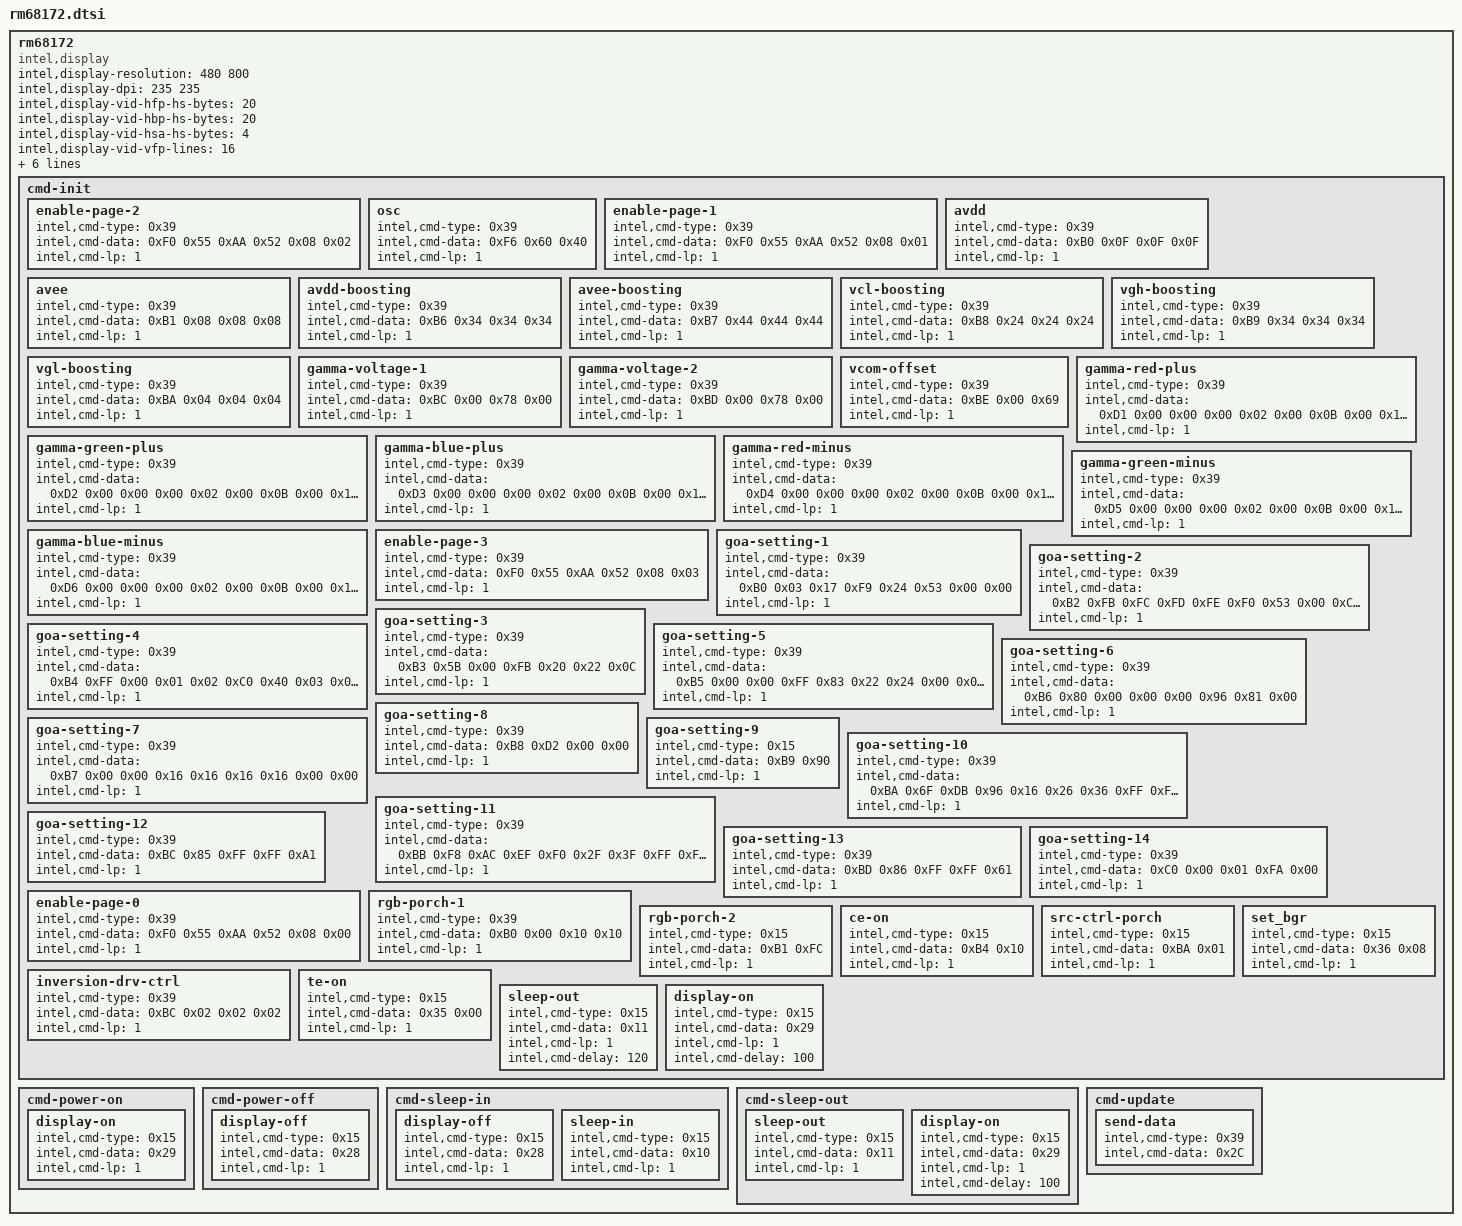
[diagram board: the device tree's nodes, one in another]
	rm68172 {
		compatible = "intel,display";
		intel,display-resolution= <480 800>;
		intel,display-dpi= <235 235>;

		/* MIPI-DSI video mode settings */
		intel,display-vid-hfp-hs-bytes = <20>;
		intel,display-vid-hbp-hs-bytes = <20>;
		intel,display-vid-hsa-hs-bytes = <4>;
		intel,display-vid-vfp-lines = <16>;
		intel,display-vid-vbp-lines = <16>;
		intel,display-vid-vsa-lines = <2>;

		intel,display-vid-mode = "burst";
		intel,display-vid-id = <0>;
		intel,display-vid-pixel = "24packed";

		intel,display-reset = <1 1 0 5 1 50>;

		cmd-init {
			enable-page-2 {
				intel,cmd-type = <0x39>;
				intel,cmd-data = <0xF0 0x55 0xAA 0x52 0x08 0x02>;
				intel,cmd-lp = <1>;
			};
			osc {
				intel,cmd-type = <0x39>;
				intel,cmd-data = <0xF6 0x60 0x40>;
				intel,cmd-lp = <1>;
			};
			enable-page-1 {
				intel,cmd-type = <0x39>;
				intel,cmd-data = <0xF0 0x55 0xAA 0x52 0x08 0x01>;
				intel,cmd-lp = <1>;
			};
			avdd {
				intel,cmd-type = <0x39>;
				intel,cmd-data = <0xB0 0x0F 0x0F 0x0F>;
				intel,cmd-lp = <1>;
			};
			avee {
				intel,cmd-type = <0x39>;
				intel,cmd-data = <0xB1 0x08 0x08 0x08>;
				intel,cmd-lp = <1>;
			};
			avdd-boosting {
				intel,cmd-type = <0x39>;
				intel,cmd-data = <0xB6 0x34 0x34 0x34>;
				intel,cmd-lp = <1>;
			};
			avee-boosting {
				intel,cmd-type = <0x39>;
				intel,cmd-data = <0xB7 0x44 0x44 0x44>;
				intel,cmd-lp = <1>;
			};
			vcl-boosting {
				intel,cmd-type = <0x39>;
				intel,cmd-data = <0xB8 0x24 0x24 0x24>;
				intel,cmd-lp = <1>;
			};
			vgh-boosting {
				intel,cmd-type = <0x39>;
				intel,cmd-data = <0xB9 0x34 0x34 0x34>;
				intel,cmd-lp = <1>;
			};
			vgl-boosting {
				intel,cmd-type = <0x39>;
				intel,cmd-data = <0xBA 0x04 0x04 0x04>;
				intel,cmd-lp = <1>;
			};
			gamma-voltage-1 {
				intel,cmd-type = <0x39>;
				intel,cmd-data = <0xBC 0x00 0x78 0x00>;
				intel,cmd-lp = <1>;
			};
			gamma-voltage-2 {
				intel,cmd-type = <0x39>;
				intel,cmd-data = <0xBD 0x00 0x78 0x00>;
				intel,cmd-lp = <1>;
			};
			vcom-offset {
				intel,cmd-type = <0x39>;
				intel,cmd-data = <0xBE 0x00 0x69>;
				intel,cmd-lp = <1>;
			};
			gamma-red-plus {
				intel,cmd-type = <0x39>;
				intel,cmd-data = <0xD1
					0x00 0x00 0x00 0x02 0x00 0x0B 0x00 0x1D 0x00 0x34
					0x00 0x6B 0x00 0x9E 0x00 0xEA 0x01 0x1E 0x01 0x63
					0x01 0x92 0x01 0xD2 0x02 0x02 0x02 0x04 0x02 0x2E
					0x02 0x57 0x02 0x6E 0x02 0x89 0x02 0x9A 0x02 0xAF
					0x02 0xBD 0x02 0xD0 0x02 0xDD 0x02 0xF2	0x03 0x22
					0x03 0xFB>;
				intel,cmd-lp = <1>;
			};
			gamma-green-plus {
				intel,cmd-type = <0x39>;
				intel,cmd-data = <0xD2
					0x00 0x00 0x00 0x02 0x00 0x0B 0x00 0x1D 0x00 0x34
					0x00 0x6B 0x00 0x9E 0x00 0xEA 0x01 0x1E 0x01 0x63
					0x01 0x92 0x01 0xD2 0x02 0x02 0x02 0x04 0x02 0x2E
					0x02 0x57 0x02 0x6E 0x02 0x89 0x02 0x9A 0x02 0xAF
					0x02 0xBD 0x02 0xD0 0x02 0xDD 0x02 0xF2 0x03 0x22
					0x03 0xFB>;
				intel,cmd-lp = <1>;
			};
			gamma-blue-plus {
				intel,cmd-type = <0x39>;
				intel,cmd-data = <0xD3
					0x00 0x00 0x00 0x02 0x00 0x0B 0x00 0x1D 0x00 0x34
					0x00 0x6B 0x00 0x9E 0x00 0xEA 0x01 0x1E 0x01 0x63
					0x01 0x92 0x01 0xD2 0x02 0x02 0x02 0x04 0x02 0x2E
					0x02 0x57 0x02 0x6E 0x02 0x89 0x02 0x9A 0x02 0xAF
					0x02 0xBD 0x02 0xD0 0x02 0xDD 0x02 0xF2 0x03 0x22
					0x03 0xFB>;
				intel,cmd-lp = <1>;
			};
			gamma-red-minus {
				intel,cmd-type = <0x39>;
				intel,cmd-data = <0xD4
					0x00 0x00 0x00 0x02 0x00 0x0B 0x00 0x1D 0x00 0x34
					0x00 0x6B 0x00 0x9E 0x00 0xEA 0x01 0x1E 0x01 0x63
					0x01 0x92 0x01 0xD2 0x02 0x02 0x02 0x04 0x02 0x2E
					0x02 0x57 0x02 0x6E 0x02 0x89 0x02 0x9A 0x02 0xAF
					0x02 0xBD 0x02 0xD0 0x02 0xDD 0x02 0xF2 0x03 0x22
					0x03 0xFB>;
				intel,cmd-lp = <1>;
			};
			gamma-green-minus {
				intel,cmd-type = <0x39>;
				intel,cmd-data = <0xD5
					0x00 0x00 0x00 0x02 0x00 0x0B 0x00 0x1D 0x00 0x34
					0x00 0x6B 0x00 0x9E 0x00 0xEA 0x01 0x1E 0x01 0x63
					0x01 0x92 0x01 0xD2 0x02 0x02 0x02 0x04 0x02 0x2E
					0x02 0x57 0x02 0x6E 0x02 0x89 0x02 0x9A 0x02 0xAF
					0x02 0xBD 0x02 0xD0 0x02 0xDD 0x02 0xF2 0x03 0x22
					0x03 0xFB>;
				intel,cmd-lp = <1>;
			};
			gamma-blue-minus {
				intel,cmd-type = <0x39>;
				intel,cmd-data = <0xD6
					0x00 0x00 0x00 0x02 0x00 0x0B 0x00 0x1D 0x00 0x34
					0x00 0x6B 0x00 0x9E 0x00 0xEA 0x01 0x1E 0x01 0x63
					0x01 0x92 0x01 0xD2 0x02 0x02 0x02 0x04 0x02 0x2E
					0x02 0x57 0x02 0x6E 0x02 0x89 0x02 0x9A 0x02 0xAF
					0x02 0xBD 0x02 0xD0 0x02 0xDD 0x02 0xF2 0x03 0x22
					0x03 0xFB>;
				intel,cmd-lp = <1>;
			};
			enable-page-3 {
				intel,cmd-type = <0x39>;
				intel,cmd-data = <0xF0 0x55 0xAA 0x52 0x08 0x03>;
				intel,cmd-lp = <1>;
			};
			goa-setting-1 {
				intel,cmd-type = <0x39>;
				intel,cmd-data = <0xB0 0x03 0x17 0xF9 0x24 0x53 0x00 0x00>;
				intel,cmd-lp = <1>;
			};
			goa-setting-2 {
				intel,cmd-type = <0x39>;
				intel,cmd-data = <0xB2 0xFB 0xFC 0xFD 0xFE 0xF0 0x53 0x00 0xC3 0x08>;
				intel,cmd-lp = <1>;
			};
			goa-setting-3 {
				intel,cmd-type = <0x39>;
				intel,cmd-data = <0xB3 0x5B 0x00 0xFB 0x20 0x22 0x0C>;
				intel,cmd-lp = <1>;
			};
			goa-setting-4 {
				intel,cmd-type = <0x39>;
				intel,cmd-data = <0xB4 0xFF 0x00 0x01 0x02 0xC0 0x40 0x03 0x08 0x53>;
				intel,cmd-lp = <1>;
			};
			goa-setting-5 {
				intel,cmd-type = <0x39>;
				intel,cmd-data = <0xB5 0x00 0x00 0xFF 0x83 0x22 0x24 0x00 0x00 0x33 0x00 0x44>;
				intel,cmd-lp = <1>;
			};
			goa-setting-6 {
				intel,cmd-type = <0x39>;
				intel,cmd-data = <0xB6 0x80 0x00 0x00 0x00 0x96 0x81 0x00>;
				intel,cmd-lp = <1>;
			};
			goa-setting-7 {
				intel,cmd-type = <0x39>;
				intel,cmd-data = <0xB7 0x00 0x00 0x16 0x16 0x16 0x16 0x00 0x00>;
				intel,cmd-lp = <1>;
			};
			goa-setting-8 {
				intel,cmd-type = <0x39>;
				intel,cmd-data = <0xB8 0xD2 0x00 0x00>;
				intel,cmd-lp = <1>;
			};
			goa-setting-9 {
				intel,cmd-type = <0x15>;
				intel,cmd-data = <0xB9 0x90>;
				intel,cmd-lp = <1>;
			};
			goa-setting-10 {
				intel,cmd-type = <0x39>;
				intel,cmd-data = <0xBA 0x6F 0xDB 0x96 0x16 0x26 0x36 0xFF 0xFF 0xFF 0xFF 0xF0 0xF1 0xF0 0xF8 0xAC 0xEF>;
				intel,cmd-lp = <1>;
			};
			goa-setting-11 {
				intel,cmd-type = <0x39>;
				intel,cmd-data = <0xBB 0xF8 0xAC 0xEF 0xF0 0x2F 0x3F 0xFF 0xFF 0xFF 0xFF 0xF0 0xF1 0x1F 0xFF 0xDB 0x9F>;
				intel,cmd-lp = <1>;
			};
			goa-setting-12 {
				intel,cmd-type = <0x39>;
				intel,cmd-data = <0xBC 0x85 0xFF 0xFF 0xA1>;
				intel,cmd-lp = <1>;
			};
			goa-setting-13 {
				intel,cmd-type = <0x39>;
				intel,cmd-data = <0xBD 0x86 0xFF 0xFF 0x61>;
				intel,cmd-lp = <1>;
			};
			goa-setting-14 {
				intel,cmd-type = <0x39>;
				intel,cmd-data = <0xC0 0x00 0x01 0xFA 0x00>;
				intel,cmd-lp = <1>;
			};
			enable-page-0 {
				intel,cmd-type = <0x39>;
				intel,cmd-data = <0xF0 0x55 0xAA 0x52 0x08 0x00>;
				intel,cmd-lp = <1>;
			};
			rgb-porch-1 {
				intel,cmd-type = <0x39>;
				intel,cmd-data = <0xB0 0x00 0x10 0x10>;
				intel,cmd-lp = <1>;
			};
			rgb-porch-2 {
				intel,cmd-type = <0x15>;
				intel,cmd-data = <0xB1 0xFC>;
				intel,cmd-lp = <1>;
			};
			ce-on {
				intel,cmd-type = <0x15>;
				intel,cmd-data = <0xB4 0x10>;
				intel,cmd-lp = <1>;
			};
			src-ctrl-porch {
				intel,cmd-type = <0x15>;
				intel,cmd-data = <0xBA 0x01>;
				intel,cmd-lp = <1>;
			};
			inversion-drv-ctrl {
				intel,cmd-type = <0x39>;
				intel,cmd-data = <0xBC 0x02 0x02 0x02>;
				intel,cmd-lp = <1>;
			};
			set_bgr {
				intel,cmd-type = <0x15>;
				intel,cmd-data = <0x36 0x08>;
				intel,cmd-lp = <1>;
			};
			te-on {
				intel,cmd-type = <0x15>;
				intel,cmd-data = <0x35 0x00>;
				intel,cmd-lp = <1>;
			};
			sleep-out {
				intel,cmd-type = <0x15>;
				intel,cmd-data = <0x11>;
				intel,cmd-lp = <1>;
				intel,cmd-delay = <120>;
			};
			display-on{
				intel,cmd-type = <0x15>;
				intel,cmd-data = <0x29>;
				intel,cmd-lp = <1>;
				intel,cmd-delay = <100>;
			};
		};

		cmd-power-on {
			display-on{
				intel,cmd-type = <0x15>;
				intel,cmd-data = <0x29>;
				intel,cmd-lp = <1>;
			};
		};

		cmd-power-off {
			display-off{
				intel,cmd-type = <0x15>;
				intel,cmd-data = <0x28>;
				intel,cmd-lp = <1>;
			};
		};

		cmd-sleep-in {
			display-off{
				intel,cmd-type = <0x15>;
				intel,cmd-data = <0x28>;
				intel,cmd-lp = <1>;
			};
			sleep-in{
				intel,cmd-type = <0x15>;
				intel,cmd-data = <0x10>;
				intel,cmd-lp = <1>;
			};
		};

		cmd-sleep-out {
			sleep-out{
				intel,cmd-type = <0x15>;
				intel,cmd-data = <0x11>;
				intel,cmd-lp = <1>;
			};
			display-on{
				intel,cmd-type = <0x15>;
				intel,cmd-data = <0x29>;
				intel,cmd-lp = <1>;
				intel,cmd-delay = <100>;
			};
		};

		cmd-update {
			send-data {
				intel,cmd-type = <0x39>;
				intel,cmd-data = <0x2C>;
			};
		};
	};
